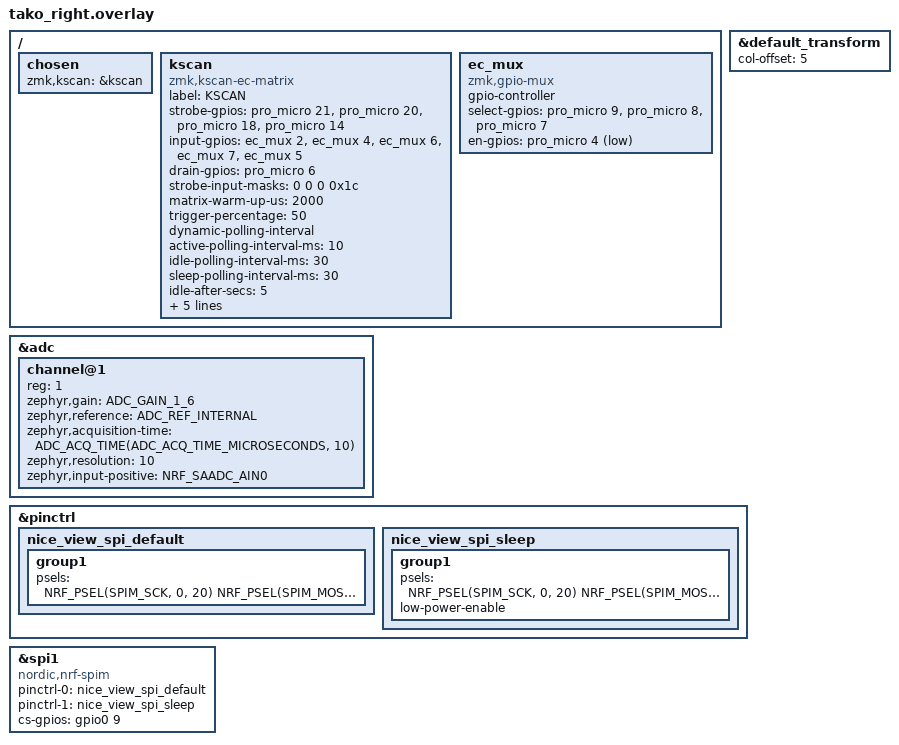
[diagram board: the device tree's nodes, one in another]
/*
 * Copyright (c) 2023 ssbb
 *
 * SPDX-License-Identifier: MIT
 */

#include "tako.dtsi"

/ {
  chosen {
    zmk,kscan = &kscan;
  };

  kscan: kscan {
    compatible = "zmk,kscan-ec-matrix";
    label = "KSCAN";
    strobe-gpios
    = <&pro_micro 21 GPIO_ACTIVE_HIGH>
    , <&pro_micro 20 GPIO_ACTIVE_HIGH>
    , <&pro_micro 18 GPIO_ACTIVE_HIGH>
    , <&pro_micro 14 GPIO_ACTIVE_HIGH>
    ;

    input-gpios =
      <&ec_mux 2 GPIO_ACTIVE_HIGH>,
      <&ec_mux 4 GPIO_ACTIVE_HIGH>,
      <&ec_mux 6 GPIO_ACTIVE_HIGH>,
      <&ec_mux 7 GPIO_ACTIVE_HIGH>,
      <&ec_mux 5 GPIO_ACTIVE_HIGH>;
    drain-gpios = <&pro_micro 6 GPIO_ACTIVE_HIGH>;
    /* Only inputs 0 and 1 exist on the thumb row. */
    strobe-input-masks = <0 0 0 0x1c>;
    matrix-warm-up-us = <2000>;
    trigger-percentage = <50>;
    dynamic-polling-interval;
    active-polling-interval-ms = <10>;
    idle-polling-interval-ms = <30>;
    // Keep key detection responsive until ZMK actually suspends the device.
    sleep-polling-interval-ms = <30>;
    idle-after-secs = <5>;
    sleep-after-secs = <900>;
    io-channels = <&adc 1>;
    /* MUX VCC shares matrix POWER. Park E and S0/S1/S2 physically low
     * before cutting POWER, matching the original Tako driver. */
    power-off-gpios = <&pro_micro 4 GPIO_ACTIVE_LOW>,
      <&pro_micro 9 GPIO_ACTIVE_HIGH>,
      <&pro_micro 8 GPIO_ACTIVE_HIGH>,
      <&pro_micro 7 GPIO_ACTIVE_HIGH>;
    power-gpios = <&pro_micro 5 GPIO_ACTIVE_HIGH>;
  };
  ec_mux: ec_mux {
    compatible = "zmk,gpio-mux";
    gpio-controller;
    #gpio-cells = <2>;
    select-gpios =
      <&pro_micro 9 GPIO_ACTIVE_HIGH>,
      <&pro_micro 8 GPIO_ACTIVE_HIGH>,
      <&pro_micro 7 GPIO_ACTIVE_HIGH>;
    /* The physical mux enable is active low. */
    en-gpios = <&pro_micro 4 GPIO_ACTIVE_LOW>;
  };

};

&default_transform {
    col-offset = <5>;
};


&adc {
  #address-cells = <1>;
  #size-cells = <0>;
  status = "okay";

  channel@1 {
    reg = <1>;
    zephyr,gain = "ADC_GAIN_1_6";
    zephyr,reference = "ADC_REF_INTERNAL";
    zephyr,acquisition-time = <ADC_ACQ_TIME(ADC_ACQ_TIME_MICROSECONDS, 10)>;
    zephyr,resolution = <10>;
    zephyr,input-positive = <NRF_SAADC_AIN0>; /* P0.02 */
  };
};


&pinctrl {
    nice_view_spi_default: nice_view_spi_default {
        group1 {
            psels = <
                NRF_PSEL(SPIM_SCK, 0, 20)
                NRF_PSEL(SPIM_MOSI, 0, 17)
            >;
        };
    };

    nice_view_spi_sleep: nice_view_spi_sleep {
        group1 {
            psels = <
                NRF_PSEL(SPIM_SCK, 0, 20)
                NRF_PSEL(SPIM_MOSI, 0, 17)
            >;
            low-power-enable;
        };
    };
};

nice_view_spi: &spi1 {
    compatible = "nordic,nrf-spim";
    status = "okay";

    pinctrl-0 = <&nice_view_spi_default>;
    pinctrl-1 = <&nice_view_spi_sleep>;
    pinctrl-names = "default", "sleep";

    cs-gpios = <&gpio0 9 GPIO_ACTIVE_HIGH>;
};
